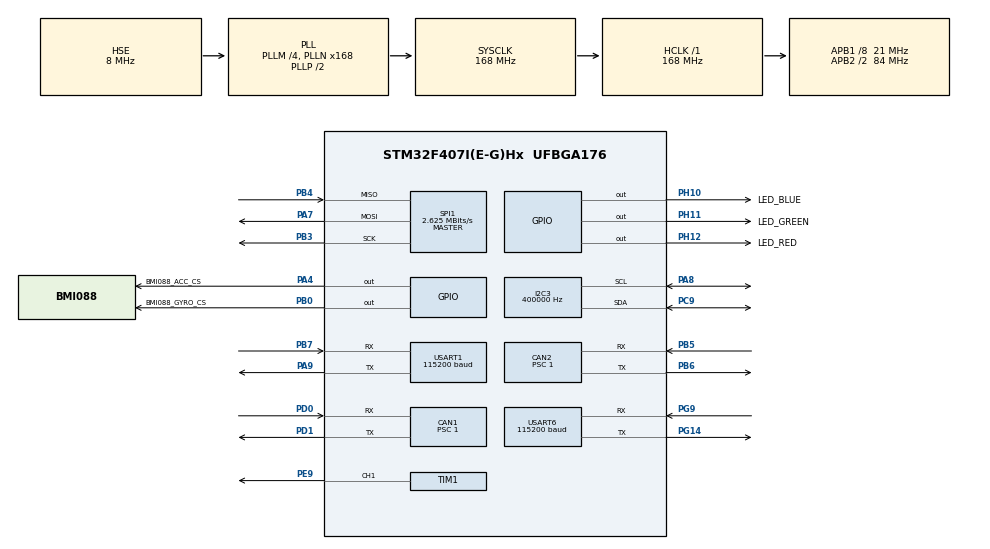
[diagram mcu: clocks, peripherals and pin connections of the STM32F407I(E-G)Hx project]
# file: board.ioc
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CAN1.BS1=CAN_BS1_16TQ
CAN1.BS2=CAN_BS2_4TQ
CAN1.CalculateBaudRate=1000000
CAN1.CalculateTimeQuantum=47.61904761904762
CAN1.Prescaler=1
CAN2.BS1=CAN_BS1_16TQ
CAN2.BS2=CAN_BS2_4TQ
CAN2.CalculateBaudRate=1000000
CAN2.CalculateTimeQuantum=47.61904761904762
CAN2.Prescaler=1
Dma.Request0=USART1_RX
Dma.Request1=USART1_TX
Dma.Request2=USART6_RX
Dma.Request3=USART6_TX
Dma.USART1_RX.0.Direction=DMA_PERIPH_TO_MEMORY
Dma.USART1_RX.0.FIFOMode=DMA_FIFOMODE_DISABLE
Dma.USART1_RX.0.Instance=DMA2_Stream2
Dma.USART1_RX.0.MemDataAlignment=DMA_MDATAALIGN_BYTE
Dma.USART1_RX.0.MemInc=DMA_MINC_ENABLE
Dma.USART1_RX.0.Mode=DMA_CIRCULAR
Dma.USART1_RX.0.PeriphDataAlignment=DMA_PDATAALIGN_BYTE
Dma.USART1_RX.0.PeriphInc=DMA_PINC_DISABLE
Dma.USART1_RX.0.Priority=DMA_PRIORITY_HIGH
Dma.USART1_TX.1.Direction=DMA_MEMORY_TO_PERIPH
Dma.USART1_TX.1.FIFOMode=DMA_FIFOMODE_DISABLE
Dma.USART1_TX.1.Instance=DMA2_Stream7
Dma.USART1_TX.1.MemDataAlignment=DMA_MDATAALIGN_BYTE
Dma.USART1_TX.1.MemInc=DMA_MINC_ENABLE
Dma.USART1_TX.1.Mode=DMA_NORMAL
Dma.USART1_TX.1.PeriphDataAlignment=DMA_PDATAALIGN_BYTE
Dma.USART1_TX.1.PeriphInc=DMA_PINC_DISABLE
Dma.USART1_TX.1.Priority=DMA_PRIORITY_LOW
Dma.USART6_RX.2.Direction=DMA_PERIPH_TO_MEMORY
Dma.USART6_RX.2.FIFOMode=DMA_FIFOMODE_DISABLE
Dma.USART6_RX.2.Instance=DMA2_Stream1
Dma.USART6_RX.2.MemDataAlignment=DMA_MDATAALIGN_BYTE
Dma.USART6_RX.2.MemInc=DMA_MINC_ENABLE
Dma.USART6_RX.2.Mode=DMA_CIRCULAR
Dma.USART6_RX.2.PeriphDataAlignment=DMA_PDATAALIGN_BYTE
Dma.USART6_RX.2.PeriphInc=DMA_PINC_DISABLE
Dma.USART6_RX.2.Priority=DMA_PRIORITY_HIGH
Dma.USART6_TX.3.Direction=DMA_MEMORY_TO_PERIPH
Dma.USART6_TX.3.FIFOMode=DMA_FIFOMODE_DISABLE
Dma.USART6_TX.3.Instance=DMA2_Stream6
Dma.USART6_TX.3.MemDataAlignment=DMA_MDATAALIGN_BYTE
Dma.USART6_TX.3.MemInc=DMA_MINC_ENABLE
Dma.USART6_TX.3.Mode=DMA_NORMAL
Dma.USART6_TX.3.PeriphDataAlignment=DMA_PDATAALIGN_BYTE
Dma.USART6_TX.3.PeriphInc=DMA_PINC_DISABLE
Dma.USART6_TX.3.Priority=DMA_PRIORITY_LOW
I2C3.ClockSpeed=400000
I2C3.I2C_Mode=I2C_Fast
Mcu.Family=STM32F4
Mcu.Name=STM32F407I(E-G)Hx
Mcu.Package=UFBGA176
NVIC.CAN1_RX0_IRQn=true\:5\:0\:false\:false\:true\:true\:true\:true
NVIC.CAN1_SCE_IRQn=true\:5\:0\:false\:false\:true\:true\:true\:true
NVIC.CAN1_TX_IRQn=true\:5\:0\:false\:false\:true\:true\:true\:true
NVIC.CAN2_RX0_IRQn=true\:5\:0\:false\:false\:true\:true\:true\:true
NVIC.CAN2_SCE_IRQn=true\:5\:0\:false\:false\:true\:true\:true\:true
NVIC.CAN2_TX_IRQn=true\:5\:0\:false\:false\:true\:true\:true\:true
NVIC.DMA2_Stream1_IRQn=true\:6\:0\:false\:false\:true\:false\:true\:true
NVIC.DMA2_Stream2_IRQn=true\:6\:0\:false\:false\:true\:false\:true\:true
NVIC.DMA2_Stream6_IRQn=true\:6\:0\:false\:false\:true\:false\:true\:true
NVIC.DMA2_Stream7_IRQn=true\:6\:0\:false\:false\:true\:false\:true\:true
NVIC.PriorityGroup=NVIC_PRIORITYGROUP_4
NVIC.TIM6_DAC_IRQn=true\:14\:0\:false\:false\:true\:false\:true\:true
NVIC.TimeBase=TIM6_DAC_IRQn
NVIC.TimeBaseIP=TIM6
NVIC.USART1_IRQn=true\:6\:0\:false\:false\:true\:true\:true\:true
NVIC.USART6_IRQn=true\:6\:0\:false\:false\:true\:true\:true\:true
PA13.Mode=Serial_Wire
PA13.Signal=SYS_JTMS-SWDIO
PA14.Mode=Serial_Wire
PA14.Signal=SYS_JTCK-SWCLK
PA4.GPIO_Label=BMI088_ACC_CS
PA4.PinState=GPIO_PIN_SET
PA4.Signal=GPIO_Output
PA7.Mode=Full_Duplex_Master
PA7.Signal=SPI1_MOSI
PA8.GPIO_PuPd=GPIO_NOPULL
PA8.Mode=I2C
PA8.Signal=I2C3_SCL
PA9.GPIO_PuPd=GPIO_PULLUP
PA9.Mode=Asynchronous
PA9.Signal=USART1_TX
PB0.GPIO_Label=BMI088_GYRO_CS
PB0.PinState=GPIO_PIN_SET
PB0.Signal=GPIO_Output
PB3.Mode=Full_Duplex_Master
PB3.Signal=SPI1_SCK
PB4.Mode=Full_Duplex_Master
PB4.Signal=SPI1_MISO
PB5.Mode=CAN_Activate
PB5.Signal=CAN2_RX
PB6.Mode=CAN_Activate
PB6.Signal=CAN2_TX
PB7.GPIO_PuPd=GPIO_PULLUP
PB7.Mode=Asynchronous
PB7.Signal=USART1_RX
PC9.GPIO_PuPd=GPIO_NOPULL
PC9.Mode=I2C
PC9.Signal=I2C3_SDA
PD0.Mode=CAN_Activate
PD0.Signal=CAN1_RX
PD1.Mode=CAN_Activate
PD1.Signal=CAN1_TX
PE9.GPIO_PuPd=GPIO_PULLDOWN
PE9.Signal=S_TIM1_CH1
PG14.GPIO_PuPd=GPIO_PULLUP
PG14.Mode=Asynchronous
PG14.Signal=USART6_TX
PG9.GPIO_PuPd=GPIO_PULLUP
PG9.Mode=Asynchronous
PG9.Signal=USART6_RX
PH0-OSC_IN.Mode=HSE-External-Oscillator
PH0-OSC_IN.Signal=RCC_OSC_IN
PH1-OSC_OUT.Mode=HSE-External-Oscillator
PH1-OSC_OUT.Signal=RCC_OSC_OUT
PH10.GPIO_Label=LED_BLUE
PH10.PinState=GPIO_PIN_SET
PH10.Signal=GPIO_Output
PH11.GPIO_Label=LED_GREEN
PH11.PinState=GPIO_PIN_SET
PH11.Signal=GPIO_Output
PH12.GPIO_Label=LED_RED
PH12.PinState=GPIO_PIN_SET
PH12.Signal=GPIO_Output
ProjectManager.HeapSize=0x400
ProjectManager.StackSize=0x1000
ProjectManager.TargetToolchain=CMake
RCC.48MHZClocksFreq_Value=48000000
RCC.AHBFreq_Value=168000000
RCC.APB1CLKDivider=RCC_HCLK_DIV8
RCC.APB1Freq_Value=21000000
RCC.APB1TimFreq_Value=42000000
RCC.APB2CLKDivider=RCC_HCLK_DIV2
RCC.APB2Freq_Value=84000000
RCC.APB2TimFreq_Value=168000000
RCC.CortexFreq_Value=168000000
RCC.HCLKFreq_Value=168000000
RCC.HSE_VALUE=8000000
RCC.HSI_VALUE=16000000
RCC.LSE_VALUE=32768
RCC.PLLM=4
RCC.PLLN=168
RCC.PLLQ=7
RCC.PLLSourceVirtual=RCC_PLLSOURCE_HSE
RCC.SYSCLKFreq_VALUE=168000000
RCC.SYSCLKSource=RCC_SYSCLKSOURCE_PLLCLK
RCC.VCOOutputFreq_Value=336000000
SH.S_TIM1_CH1.0=TIM1_CH1,PWM Generation1 CH1
SPI1.BaudRatePrescaler=SPI_BAUDRATEPRESCALER_32
SPI1.CalculateBaudRate=2.625 MBits/s
SPI1.Direction=SPI_DIRECTION_2LINES
SPI1.Mode=SPI_MODE_MASTER
SPI1.VirtualType=VM_MASTER
TIM1.Channel-PWM\ Generation1\ CH1=TIM_CHANNEL_1
TIM1.Period=19999
TIM1.Prescaler=167
TIM1.Pulse-PWM\ Generation1\ CH1=0
USART1.BaudRate=115200
USART1.VirtualMode=VM_ASYNC
USART6.BaudRate=115200
USART6.VirtualMode=VM_ASYNC
VP_SYS_VS_tim6.Mode=TIM6
VP_TIM1_VS_ClockSourceINT.Mode=Internal
board=custom

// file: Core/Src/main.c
/* USER CODE BEGIN Header */
/**
  ******************************************************************************
  * @file           : main.c
  * @brief          : Main program body
  ******************************************************************************
  * @attention
  *
  * Copyright (c) 2026 STMicroelectronics.
  * All rights reserved.
  *
  * This software is licensed under terms that can be found in the LICENSE file
  * in the root directory of this software component.
  * If no LICENSE file comes with this software, it is provided AS-IS.
  *
  ******************************************************************************
  */
/* USER CODE END Header */
#include "main.h"
#include "can.h"
#include "dma.h"
#include "i2c.h"
#include "spi.h"
#include "tim.h"
#include "usart.h"
#include "gpio.h"

void SystemClock_Config(void);
/* USER CODE BEGIN PFP */
#ifdef APP_BUILD_SERVICES
void app_start(void);
#endif
/* USER CODE END PFP */

int main(void)
{

  /* MCU Configuration--------------------------------------------------------*/

  /* Reset of all peripherals, Initializes the Flash interface and the Systick. */
  HAL_Init();

  /* Configure the system clock */
  SystemClock_Config();

  /* Initialize all configured peripherals */
  MX_GPIO_Init();
  MX_DMA_Init();
  MX_CAN1_Init();
  MX_CAN2_Init();
  MX_SPI1_Init();
  MX_I2C3_Init();
  MX_USART1_UART_Init();
  MX_USART6_UART_Init();
  MX_TIM1_Init();
  /* USER CODE BEGIN 2 */
#ifdef APP_BUILD_SERVICES
  app_start();
#endif
  /* USER CODE END 2 */

  /* Infinite loop */
  while (1)
  {

    /* USER CODE BEGIN 3 */
    /* Minimal Board: no actuator output or busy spin; TIM6 keeps HAL time. */
    __WFI();
  }
  /* USER CODE END 3 */
}

void SystemClock_Config(void)
{
  RCC_OscInitTypeDef RCC_OscInitStruct = {0};
  RCC_ClkInitTypeDef RCC_ClkInitStruct = {0};

  /** Configure the main internal regulator output voltage
  */
  __HAL_RCC_PWR_CLK_ENABLE();
  __HAL_PWR_VOLTAGESCALING_CONFIG(PWR_REGULATOR_VOLTAGE_SCALE1);

  /** Initializes the RCC Oscillators according to the specified parameters
  * in the RCC_OscInitTypeDef structure.
  */
  RCC_OscInitStruct.OscillatorType = RCC_OSCILLATORTYPE_HSE;
  RCC_OscInitStruct.HSEState = RCC_HSE_ON;
  RCC_OscInitStruct.PLL.PLLState = RCC_PLL_ON;
  RCC_OscInitStruct.PLL.PLLSource = RCC_PLLSOURCE_HSE;
  RCC_OscInitStruct.PLL.PLLM = 4;
  RCC_OscInitStruct.PLL.PLLN = 168;
  RCC_OscInitStruct.PLL.PLLP = RCC_PLLP_DIV2;
  RCC_OscInitStruct.PLL.PLLQ = 7;
  if (HAL_RCC_OscConfig(&RCC_OscInitStruct) != HAL_OK)
  {
    Error_Handler();
  }

  /** Initializes the CPU, AHB and APB buses clocks
  */
  RCC_ClkInitStruct.ClockType = RCC_CLOCKTYPE_HCLK|RCC_CLOCKTYPE_SYSCLK
                              |RCC_CLOCKTYPE_PCLK1|RCC_CLOCKTYPE_PCLK2;
  RCC_ClkInitStruct.SYSCLKSource = RCC_SYSCLKSOURCE_PLLCLK;
  RCC_ClkInitStruct.AHBCLKDivider = RCC_SYSCLK_DIV1;
  RCC_ClkInitStruct.APB1CLKDivider = RCC_HCLK_DIV8;
  RCC_ClkInitStruct.APB2CLKDivider = RCC_HCLK_DIV2;

  if (HAL_RCC_ClockConfig(&RCC_ClkInitStruct, FLASH_LATENCY_5) != HAL_OK)
  {
    Error_Handler();
  }
}

void HAL_TIM_PeriodElapsedCallback(TIM_HandleTypeDef *htim)
{
  if (htim->Instance == TIM6)
  {
    HAL_IncTick();
  }
}

void Error_Handler(void)
{
  __disable_irq();
  while (1)
  {
  }
}
